# MMCSD0_SS_CFG register map
Vendor: Texas Instruments
Peripheral module from a debugger description file (folder am65x).
Registers are 32-bit, access per field, reset 0x0 unless marked. A register's access mark holds for its fields unless they carry their own. Offsets are as the file gives them; lines under a group give offsets from that group; [hi:lo] are bit positions; {n}, {i} and the like mark numbered series; 'fields as' and 'values as' point back to an identical list; <NAME> marks a mode.

## MMCSD0_SS_CFG
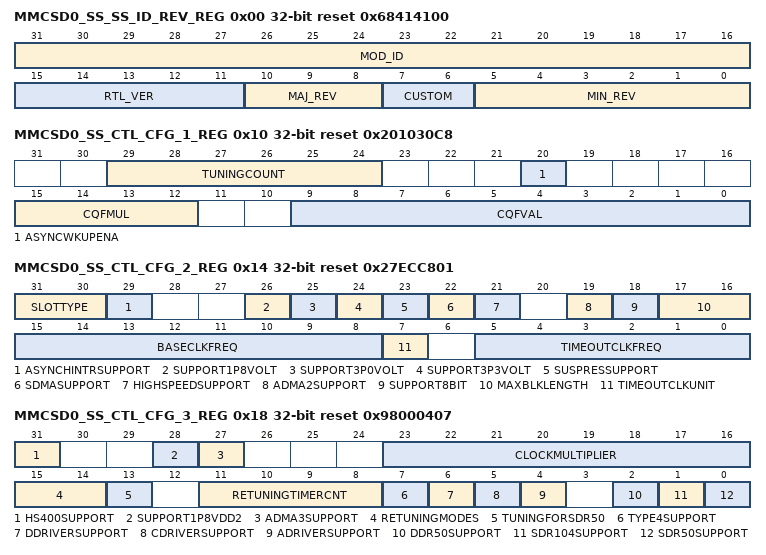
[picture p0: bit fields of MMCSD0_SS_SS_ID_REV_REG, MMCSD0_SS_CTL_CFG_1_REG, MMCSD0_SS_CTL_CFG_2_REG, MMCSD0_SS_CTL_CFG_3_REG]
0x00 MMCSD0_SS_SS_ID_REV_REG ro reset 0x68414100 — The Subsystem ID and Revision Register contains the module ID, major, and minor revisions for the subsystem.
  [31:16] MOD_ID — Module ID
  [15:11] RTL_VER — RTL Version
  [10:8] MAJ_REV — Major Version
  [7:6] CUSTOM — Custom Version
  [5:0] MIN_REV — Minor Version
0x10 MMCSD0_SS_CTL_CFG_1_REG reset 0x201030C8 — The Controller Config 1 Register contains various fields to control the configuration ports on the Host Controller. For detailed functionality of the Host Controller configuration ports please refer to its specification.
  [29:24] TUNINGCOUNT rw — This field controls the corecfg_tuningcount port on the controller.
  [20] ASYNCWKUPENA rw — This field controls the corecfg_asyncwkupena port on the controller.
  [15:12] CQFMUL rw — This field controls the corecfg_cqfmul port on the controller.
  [9:0] CQFVAL rw — This field controls the corecfg_cqfval port on the controller.
0x14 MMCSD0_SS_CTL_CFG_2_REG reset 0x27ECC801 — The Controller Config 2 Register contains various fields to control the configuration ports on the Host Controller. For detailed functionality of the Host Controller configuration ports please refer to its specification. This register sets the LSB fields in the register inside the Host Controller.
  [31:30] SLOTTYPE rw — This field controls the corecfg_slottype port on the controller.
  [29] ASYNCHINTRSUPPORT rw — This field controls the corecfg_asynchintrsupport port on the controller.
  [26] SUPPORT1P8VOLT rw — This field controls the corecfg_1p8voltsupport port on the controller.
  [25] SUPPORT3P0VOLT rw — This field controls the corecfg_3p0voltsupport port on the controller.
  [24] SUPPORT3P3VOLT rw — This field controls the corecfg_3p3voltsupport port on the controller.
  [23] SUSPRESSUPPORT rw — This field controls the corecfg_suspressupport port on the controller.
  [22] SDMASUPPORT rw — This field controls the corecfg_sdmasupport port on the controller.
  [21] HIGHSPEEDSUPPORT rw — This field controls the corecfg_highspeedsupport port on the controller.
  [19] ADMA2SUPPORT rw — This field controls the corecfg_adma2support port on the controller.
  [18] SUPPORT8BIT rw — This field controls the corecfg_8bitsupport port on the controller.
  [17:16] MAXBLKLENGTH rw — This field controls the corecfg_maxblklength port on the controller.
  [15:8] BASECLKFREQ rw — This field controls the corecfg_baseclkfreq port on the controller.
  [7] TIMEOUTCLKUNIT rw — This field controls the corecfg_timeoutclkunit port on the controller.
  [5:0] TIMEOUTCLKFREQ rw — This field controls the corecfg_timeoutclkfreq port on the controller.
0x18 MMCSD0_SS_CTL_CFG_3_REG reset 0x98000407 — The Controller Config 3 Register contains various fields to control the configuration ports on the Host Controller. For detailed functionality of the Host Controller configuration ports please refer to its specification. This register sets the MSB fields in the register inside the Host Controller.
  [31] HS400SUPPORT rw — This field controls the corecfg_hs400support port on the controller.
  [28] SUPPORT1P8VDD2 rw — This field controls the corecfg_1p8vdd2support port on the controller.
  [27] ADMA3SUPPORT rw — This field controls the corecfg_adma3support port on the controller.
  [23:16] CLOCKMULTIPLIER rw — This field controls the corecfg_clockmultiplier port on the controller.
  [15:14] RETUNINGMODES rw — This field controls the corecfg_retuningmodes port on the controller.
  [13] TUNINGFORSDR50 rw — This field controls the corecfg_tuningforsdr50 port on the controller.
  [11:8] RETUNINGTIMERCNT rw — This field controls the corecfg_retuningtimercnt port on the controller.
  [7] TYPE4SUPPORT rw — This field controls the corecfg_type4support port on the controller.
  [6] DDRIVERSUPPORT rw — This field controls the corecfg_ddriversupport port on the controller.
  [5] CDRIVERSUPPORT rw — This field controls the corecfg_cdriversupport port on the controller.
  [4] ADRIVERSUPPORT rw — This field controls the corecfg_adriversupport port on the controller.
  [2] DDR50SUPPORT rw — This field controls the corecfg_ddr50support port on the controller.
  [1] SDR104SUPPORT rw — This field controls the corecfg_sdr104support port on the controller.
  [0] SDR50SUPPORT rw — This field controls the corecfg_sdr50support port on the controller.
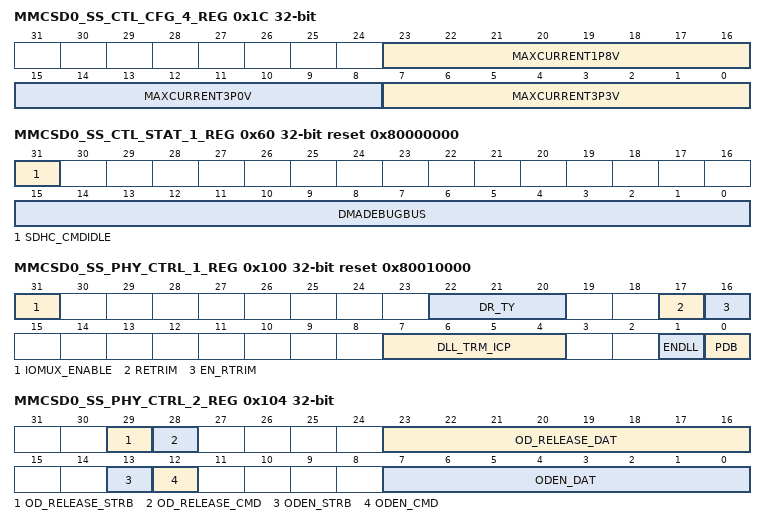
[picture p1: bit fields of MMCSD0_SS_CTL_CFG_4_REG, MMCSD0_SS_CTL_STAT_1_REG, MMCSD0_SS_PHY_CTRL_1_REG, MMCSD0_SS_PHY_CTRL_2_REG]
0x1C MMCSD0_SS_CTL_CFG_4_REG — The Controller Config 4 Register contains various fields to control the configuration ports on the Host Controller. For detailed functionality of the Host Controller configuration ports please refer to its specification. This register sets the LSB fields in the register inside the Host Controller.
  [23:16] MAXCURRENT1P8V rw — This field controls the corecfg_maxcurrent1p8v port on the controller.
  [15:8] MAXCURRENT3P0V rw — This field controls the corecfg_maxcurrent3p0v port on the controller.
  [7:0] MAXCURRENT3P3V rw — This field controls the corecfg_maxcurrent3p3v port on the controller.
0x20 MMCSD0_SS_CTL_CFG_5_REG — The Controller Config 5 Register contains various fields to control the configuration ports on the Host Controller. For detailed functionality of the Host Controller configuration ports please refer to its specification. This register sets the MSB fields in the register inside the Host Controller.
  [7:0] MAXCURRENTVDD2 rw — This field controls the corecfg_maxcurrentvdd2 port on the controller.
0x24 MMCSD0_SS_CTL_CFG_6_REG reset 0x100 — The Controller Config 6 Register contains various fields to control the configuration ports on the Host Controller. For detailed functionality of the Host Controller configuration ports please refer to its specification. This register sets the fields in the Preset Values registers ( to ) for Initialization inside the Host Controller.
  [12:0] INITPRESETVAL rw — This field controls the corecfg_initpresetval port on the controller.
0x28 MMCSD0_SS_CTL_CFG_7_REG reset 0x4 — The Controller Config 7 Register contains various fields to control the configuration ports on the Host Controller. For detailed functionality of the Host Controller configuration ports please refer to its specification. This register sets the fields in the Preset Values registers ( to ) for Default Speed inside the Host Controller.
  [12:0] DSPDPRESETVAL rw — This field controls the corecfg_dspdpresetval port on the controller.
0x2C MMCSD0_SS_CTL_CFG_8_REG reset 0x2 — The Controller Config 8 Register contains various fields to control the configuration ports on the Host Controller. For detailed functionality of the Host Controller configuration ports please refer to its specification. This register sets the fields in the Preset Values registers ( to ) for High Speed inside the Host Controller.
  [12:0] HSPDPRESETVAL rw — This field controls the corecfg_hspdpresetval port on the controller.
0x30 MMCSD0_SS_CTL_CFG_9_REG reset 0x4 — The Controller Config 9 Register contains various fields to control the configuration ports on the Host Controller. For detailed functionality of the Host Controller configuration ports please refer to its specification. This register sets the fields in the Preset Values registers ( to ) for SDR12 inside the Host Controller.
  [12:0] SDR12PRESETVAL rw — This field controls the corecfg_sdr12presetval port on the controller.
0x34 MMCSD0_SS_CTL_CFG_10_REG reset 0x2 — The Controller Config 10 Register contains various fields to control the configuration ports on the Host Controller. For detailed functionality of the Host Controller configuration ports please refer to its specification. This register sets the fields in the Preset Values registers ( to ) for SDR25 inside the Host Controller.
  [12:0] SDR25PRESETVAL rw — This field controls the corecfg_sdr25presetval port on the controller.
0x38 MMCSD0_SS_CTL_CFG_11_REG reset 0x1 — The Controller Config 11 Register contains various fields to control the configuration ports on the Host Controller. For detailed functionality of the Host Controller configuration ports please refer to its specification. This register sets the fields in the Preset Values registers ( to ) for SDR50 inside the Host Controller.
  [12:0] SDR50PRESETVAL rw — This field controls the corecfg_sdr50presetval port on the controller.
0x3C MMCSD0_SS_CTL_CFG_12_REG — The Controller Config 12 Register contains various fields to control the configuration ports on the Host Controller. For detailed functionality of the Host Controller configuration ports please refer to its specification. This register sets the fields in the Preset Values registers ( to ) for SDR104 inside the Host Controller.
  [12:0] SDR104PRESETVAL rw — This field controls the corecfg_sdr104presetval port on the controller.
0x40 MMCSD0_SS_CTL_CFG_13_REG reset 0x2 — The Controller Config 13 Register contains various fields to control the configuration ports on the Host Controller. For detailed functionality of the Host Controller configuration ports please refer to its specification. This register sets the fields in the Preset Values registers ( to ) for DDR50 inside the Host Controller.
  [12:0] DDR50PRESETVAL rw — This field controls the corecfg_ddr50presetval port on the controller.
0x44 MMCSD0_SS_CTL_CFG_14_REG reset 0x1 — The Controller Config 14 Register contains various fields to control the configuration ports on the Host Controller. For detailed functionality of the Host Controller configuration ports please refer to its specification. This register sets the fields in the Preset Values registers ( to ) for HS400 inside the Host Controller.
  [12:0] HS400PRESETVAL rw — This field controls the corecfg_hs400presetval port on the controller.
0x60 MMCSD0_SS_CTL_STAT_1_REG ro reset 0x80000000 — The Controller Status 1 Register contains various fields to reflect the status of the debug ports on the Host Controller. For detailed functionality of the Host Controller debug ports please refer to its specification.
  [31] SDHC_CMDIDLE — This field reflects the value of the sdhc_cmdidle port on the controller.
  [15:0] DMADEBUGBUS — This field reflects the value of the sdhc_dmadebugbus port on the controller.
0x64 MMCSD0_SS_CTL_STAT_2_REG ro reset 0x10 — The Controller Status 2 Register contains various fields to reflect the status of the debug ports on the Host Controller. For detailed functionality of the Host Controller debug ports please refer to its specification.
  [15:0] CMDDEBUGBUS — This field reflects the value of the sdhc_cmddebugbus port on the controller.
0x68 MMCSD0_SS_CTL_STAT_3_REG ro — The Controller Status 3 Register contains various fields to reflect the status of the debug ports on the Host Controller. For detailed functionality of the Host Controller debug ports please refer to its specification.
  [15:0] TXDDEBUGBUS — This field reflects the value of the sdhc_txddebugbus port on the controller.
0x6C MMCSD0_SS_CTL_STAT_4_REG ro — The Controller Status 4 Register contains various fields to reflect the status of the debug ports on the Host Controller. For detailed functionality of the Host Controller debug ports please refer to its specification.
  [15:0] RXDDEBUGBUS0 — This field reflects the value of the sdhc_rxddebugbus0 port on the controller.
0x70 MMCSD0_SS_CTL_STAT_5_REG ro reset 0x8 — The Controller Status 5 Register contains various fields to reflect the status of the debug ports on the Host Controller. For detailed functionality of the Host Controller debug ports please refer to its specification.
  [15:0] RXDDEBUGBUS1 — This field reflects the value of the sdhc_rxddebugbus1 port on the controller.
0x74 MMCSD0_SS_CTL_STAT_6_REG ro — The Controller Status 6 Register contains various fields to reflect the status of the debug ports on the Host Controller. For detailed functionality of the Host Controller debug ports please refer to its specification.
  [15:0] TUNDEBUGBUS — This field reflects the value of the sdhc_tundebugbus port on the controller.
0x100 MMCSD0_SS_PHY_CTRL_1_REG reset 0x80010000 — The PHY Control 1 Register contains various fields to control the ports on the Host Controller PHY. For detailed functionality of the Host Controller PHY control ports please refer to its specification.
  [31] IOMUX_ENABLE rw — This field controls the phyctrl_enable_iomuxing port on the PHY.
  [22:20] DR_TY rw — This field controls the phyctrl_dr_ty port on the PHY.
  [17] RETRIM rw — This field controls the phyctrl_retrim port on the PHY.
  [16] EN_RTRIM rw — This field controls the phyctrl_en_rtrim port on the PHY.
  [7:4] DLL_TRM_ICP rw — This field controls the phyctrl_dll_trm_icp port on the PHY.
  [1] ENDLL rw — This field controls the phyctrl_endll port on the PHY.
  [0] PDB rw — This field controls the phyctrl_pdb port on the PHY.
0x104 MMCSD0_SS_PHY_CTRL_2_REG — The PHY Control 2 Register contains various fields to control the ports on the Host Controller PHY. For detailed functionality of the Host Controller PHY control ports please refer to its specification.
  [29] OD_RELEASE_STRB rw — This field controls the phyctrl_OD_release_strb port on the PHY.
  [28] OD_RELEASE_CMD rw — This field controls the phyctrl_OD_release_cmd port on the PHY.
  [23:16] OD_RELEASE_DAT rw — This field controls the phyctrl_OD_release_dat port on the PHY.
  [13] ODEN_STRB rw — This field controls the phyctrl_oden_strb port on the PHY.
  [12] ODEN_CMD rw — This field controls the phyctrl_oden_cmd port on the PHY.
  [7:0] ODEN_DAT rw — This field controls the phyctrl_oden_dat port on the PHY.
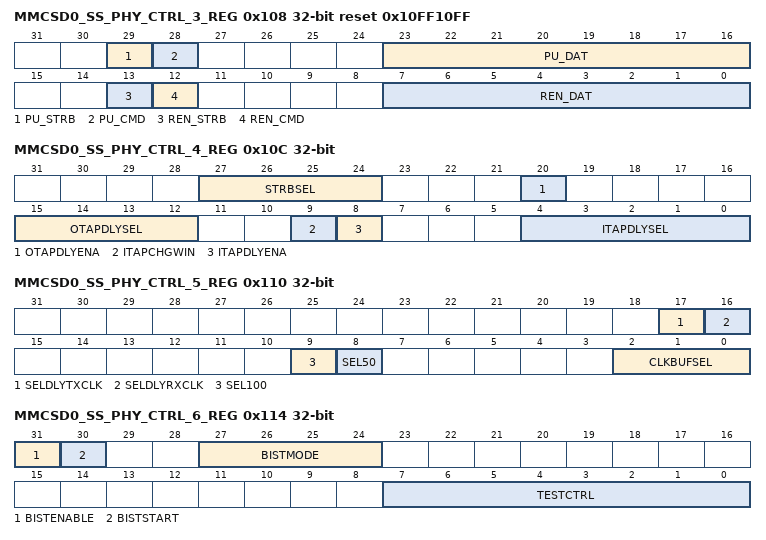
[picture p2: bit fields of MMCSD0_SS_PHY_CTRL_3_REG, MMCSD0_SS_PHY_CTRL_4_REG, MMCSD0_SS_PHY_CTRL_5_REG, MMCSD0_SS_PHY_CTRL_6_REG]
0x108 MMCSD0_SS_PHY_CTRL_3_REG reset 0x10FF10FF — The PHY Control 3 Register contains various fields to control the ports on the Host Controller PHY. For detailed functionality of the Host Controller PHY control ports please refer to its specification.
  [29] PU_STRB rw — This field controls the phyctrl_pu_strb port on the PHY.
  [28] PU_CMD rw — This field controls the phyctrl_pu_cmd port on the PHY.
  [23:16] PU_DAT rw — This field controls the phyctrl_pu_dat port on the PHY.
  [13] REN_STRB rw — This field controls the phyctrl_ren_strb port on the PHY.
  [12] REN_CMD rw — This field controls the phyctrl_ren_cmd port on the PHY.
  [7:0] REN_DAT rw — This field controls the phyctrl_ren_dat port on the PHY.
0x10C MMCSD0_SS_PHY_CTRL_4_REG — The PHY Control 4 Register contains various fields to control the ports on the Host Controller PHY. For detailed functionality of the Host Controller PHY control ports please refer to its specification.
  [27:24] STRBSEL rw — This field controls the phyctrl_strbsel port on the PHY.
  [20] OTAPDLYENA rw — This field controls the phyctrl_otapdlyena port on the PHY.
  [15:12] OTAPDLYSEL rw — This field controls the phyctrl_otapdlysel port on the PHY.
  [9] ITAPCHGWIN rw — This field controls the phyctrl_itapchgwin port on the PHY.
  [8] ITAPDLYENA rw — This field controls the phyctrl_itapdlyena port on the PHY.
  [4:0] ITAPDLYSEL rw — This field controls the phyctrl_itapdlysel port on the PHY.
0x110 MMCSD0_SS_PHY_CTRL_5_REG — The PHY Control 5 Register contains various fields to control the ports on the Host Controller PHY. For detailed functionality of the Host Controller PHY control ports please refer to its specification.
  [17] SELDLYTXCLK rw — This field controls the phyctrl_seldlytxclk port on the PHY.
  [16] SELDLYRXCLK rw — This field controls the phyctrl_seldlyrxclk port on the PHY.
  [9] SEL100 rw — This field controls the phyctrl_sel100 port on the PHY.
  [8] SEL50 rw — This field controls the phyctrl_sel50 port on the PHY.
  [2:0] CLKBUFSEL rw — This field controls the phyctrl_clkbufsel port on the PHY.
0x114 MMCSD0_SS_PHY_CTRL_6_REG — The PHY Control 6 Register contains various fields to control the ports on the Host Controller PHY. For detailed functionality of the Host Controller PHY control ports please refer to its specification.
  [31] BISTENABLE rw — This field controls the phyctrl_bistenable port on the PHY.
  [30] BISTSTART rw — This field controls the phyctrl_biststart port on the PHY.
  [27:24] BISTMODE rw — This field controls the phyctrl_bistmode port on the PHY.
  [7:0] TESTCTRL rw — This field controls the phyctrl_testctrl port on the PHY.
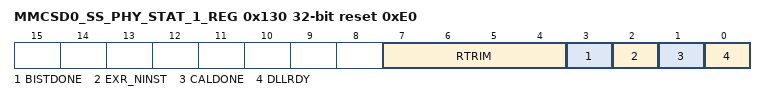
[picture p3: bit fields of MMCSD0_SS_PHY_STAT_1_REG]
0x130 MMCSD0_SS_PHY_STAT_1_REG ro reset 0xE0 — The PHY Status 1 Register contains various fields to reflect the status of the Host Controller PHY ports. For detailed functionality of the Host Controller PHY status ports please refer to its specification.
  [7:4] RTRIM — This field reflects the value of the phyctrl_rtrim port on the PHY.
  [3] BISTDONE — This field reflects the value of the phyctrl_bistdone port on the PHY.
  [2] EXR_NINST — This field reflects the value of the phyctrl_exr_ninst port on the PHY.
  [1] CALDONE — This field reflects the value of the phyctrl_caldone port on the PHY.
  [0] DLLRDY — This field reflects the value of the phyctrl_dllrdy port on the PHY.
0x134 MMCSD0_SS_PHY_STAT_2_REG ro — The PHY Status 2 Register contains various fields to reflect the status of the Host Controller PHY ports. For detailed functionality of the Host Controller PHY status ports please refer to its specification.
  [31:0] BISTSTATUS — This field reflects the value of the phyctrl_biststatus port on the PHY.
